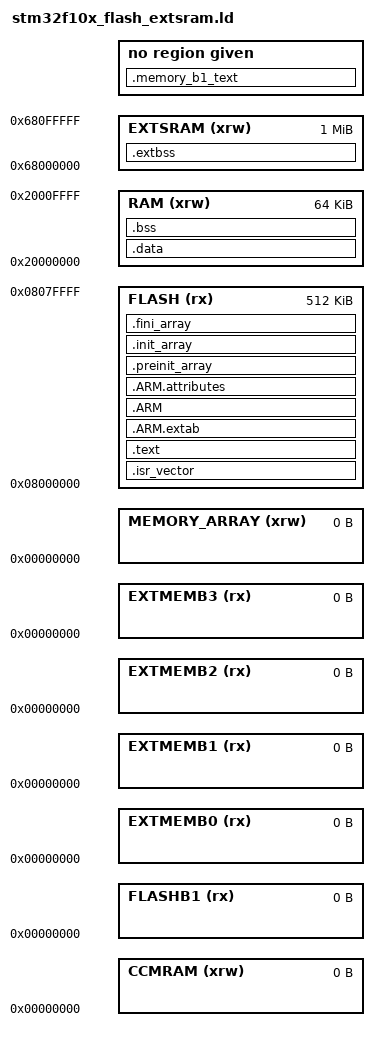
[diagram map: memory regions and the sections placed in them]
/*
*****************************************************************************
**
**  File        : stm32f10x_flash_extsram.ld
**
**  Abstract    : Linker script for STM32F10x XL-density Devices with
**                1MByte FLASH, 96KByte RAM
**
**                Set heap size, stack size and stack location according
**                to application requirements.
**
**                Set memory bank area and size if external memory is used.
**
**  Target      : STMicroelectronics STM32
**
**  Environment : Atollic TrueSTUDIO(R)
**
**  Distribution: The file is distributed ?as is,? without any warranty
**                of any kind.
**
**  (c)Copyright Atollic AB.
**  You may use this file as-is or modify it according to the needs of your
**  project. Distribution of this file (unmodified or modified) is not
**  permitted. Atollic AB permit registered Atollic TrueSTUDIO(R) users the
**  rights to distribute the assembled, compiled & linked contents of this
**  file as part of an application binary file, provided that it is built
**  using the Atollic TrueSTUDIO(R) toolchain.
**
*****************************************************************************
*/

/* Specify the memory areas */
MEMORY
{
  RAM (xrw) : ORIGIN = 0x20000000, LENGTH = 64K
  EXTSRAM (xrw) : ORIGIN = 0x68000000, LENGTH = 1024K   /* 添加外部SRAM内存区域 */
  CCMRAM (xrw) : ORIGIN = 0x00000000, LENGTH = 0
  FLASH (rx) : ORIGIN = 0x08000000, LENGTH = 512K
  FLASHB1 (rx) : ORIGIN = 0x00000000, LENGTH = 0
  EXTMEMB0 (rx) : ORIGIN = 0x00000000, LENGTH = 0
  EXTMEMB1 (rx) : ORIGIN = 0x00000000, LENGTH = 0
  EXTMEMB2 (rx) : ORIGIN = 0x00000000, LENGTH = 0
  EXTMEMB3 (rx) : ORIGIN = 0x00000000, LENGTH = 0
  MEMORY_ARRAY (xrw)  : ORIGIN = 0x00000000, LENGTH = 0
}

_estack = ORIGIN(RAM) + LENGTH(RAM);

/* Entry Point */
ENTRY(Reset_Handler)

/* Generate a link error if heap and stack don't fit into RAM */
_Min_Heap_Size = 0;      /* required amount of heap  */
_Min_Stack_Size = 0x200; /* required amount of stack */

/* Define output sections */
SECTIONS
{
  /* The startup code goes first into FLASH */
  .isr_vector :
  {
    . = ALIGN(4);
    KEEP(*(.isr_vector)) /* Startup code */
    . = ALIGN(4);
  } >FLASH

  /* The program code and other data goes into FLASH */
  .text :
  {
    . = ALIGN(4);
    *(.text)           /* .text sections (code) */
    *(.text*)          /* .text* sections (code) */
    *(.rodata)         /* .rodata sections (constants, strings, etc.) */
    *(.rodata*)        /* .rodata* sections (constants, strings, etc.) */
    *(.glue_7)         /* glue arm to thumb code */
    *(.glue_7t)        /* glue thumb to arm code */

    KEEP (*(.init))
    KEEP (*(.fini))

    . = ALIGN(4);
    _etext = .;        /* define a global symbols at end of code */
  } >FLASH


   .ARM.extab   : { *(.ARM.extab* .gnu.linkonce.armextab.*) } >FLASH
    .ARM : {
    __exidx_start = .;
      *(.ARM.exidx*)
      __exidx_end = .;
    } >FLASH

  .ARM.attributes : { *(.ARM.attributes) } > FLASH

  .preinit_array     :
  {
    PROVIDE_HIDDEN (__preinit_array_start = .);
    KEEP (*(.preinit_array*))
    PROVIDE_HIDDEN (__preinit_array_end = .);
  } >FLASH
  .init_array :
  {
    PROVIDE_HIDDEN (__init_array_start = .);
    KEEP (*(SORT(.init_array.*)))
    KEEP (*(.init_array*))
    PROVIDE_HIDDEN (__init_array_end = .);
  } >FLASH
  .fini_array :
  {
    PROVIDE_HIDDEN (__fini_array_start = .);
    KEEP (*(.fini_array*))
    KEEP (*(SORT(.fini_array.*)))
    PROVIDE_HIDDEN (__fini_array_end = .);
  } >FLASH

  /* used by the startup to initialize data */
  _sidata = .;

  /* Initialized data sections goes into RAM, load LMA copy after code */
  .data : AT ( _sidata )
  {
    . = ALIGN(4);
    _sdata = .;        /* create a global symbol at data start */
    *(.data)           /* .data sections */
    *(.data*)          /* .data* sections */

    . = ALIGN(4);
    _edata = .;        /* define a global symbol at data end */
  } >RAM

  /* Uninitialized data section */
  . = ALIGN(4);
  .bss :
  {
    /* This is used by the startup in order to initialize the .bss secion */
    _sbss = .;         /* define a global symbol at bss start */
    __bss_start__ = _sbss;
    *(.bss)
    *(.bss*)
    *(COMMON)

    . = ALIGN(4);
    _ebss = .;         /* define a global symbol at bss end */
    __bss_end__ = _ebss;
  } >RAM

  PROVIDE ( end = _ebss );
  PROVIDE ( _end = _ebss );

  /* User_heap_stack section, used to check that there is enough RAM left */
  /*
   * ._user_heap_stack :
   * {
   *   . = ALIGN(4);
   *   . = . + _Min_Heap_Size;
   *   . = . + _Min_Stack_Size;
   *   . = ALIGN(4);
   * } >RAM
   */

  /* MEMORY_bank1 section, code must be located here explicitly            */
  /* Example: extern int foo(void) __attribute__ ((section (".mb1text"))); */
  .memory_b1_text :
  {
    *(.mb1text)        /* .mb1text sections (code) */
    *(.mb1text*)       /* .mb1text* sections (code)  */
    *(.mb1rodata)      /* read-only data (constants) */
    *(.mb1rodata*)
  } >MEMORY_B1

  /****************************************************************/
  /* _Heap_Begin符号在链接脚本中定义，在_sbrk中被使用。它是堆的首字节。*/
  /* _Heap_Limit符号在链接脚本中定义，在_sbrk中被使用。它是堆的尾字节。*/
  PROVIDE ( _Heap_Begin = _heap_begin);
  PROVIDE ( _Heap_Limit = ORIGIN(EXTSRAM) + LENGTH(EXTSRAM) );
  /* 在外部SRAM的里新建一个段,用来存放比较大的全局变量。*/
  /* 使用方式是在类型和变量名之间加上 __attribute__ ((section(".extbss"))) */
  /* 比如：char __attribute__ ((section(".extbss"))) array[1024 * 65], 数组 */
  /* array[]就被定义在了外部SRAM中。注意:定义在外部SRAM中的全局变量无法初始化。*/
  .extbss : AT (0x68000000) ALIGN(4)  /* 设置.extbss段的起始地址为外部SRAM的首地址 */
  {
      *(.extbss .extbss.*);       /* 把所有输入文件的.extbss段合并到输出文件的.extbss段 */
      _heap_begin = .;            /* 堆的起始地址为输出文件.extbss段之后的第一个字节地址 */   
  } >EXTSRAM                      /* 设置.extbss段放在外部SRAM中 */
  /****************************************************************/

  /* Remove information from the standard libraries */
  /DISCARD/ :
  {
    libc.a ( * )
    libm.a ( * )
    libgcc.a ( * )
    libstdc++.a ( * )
  }
}
